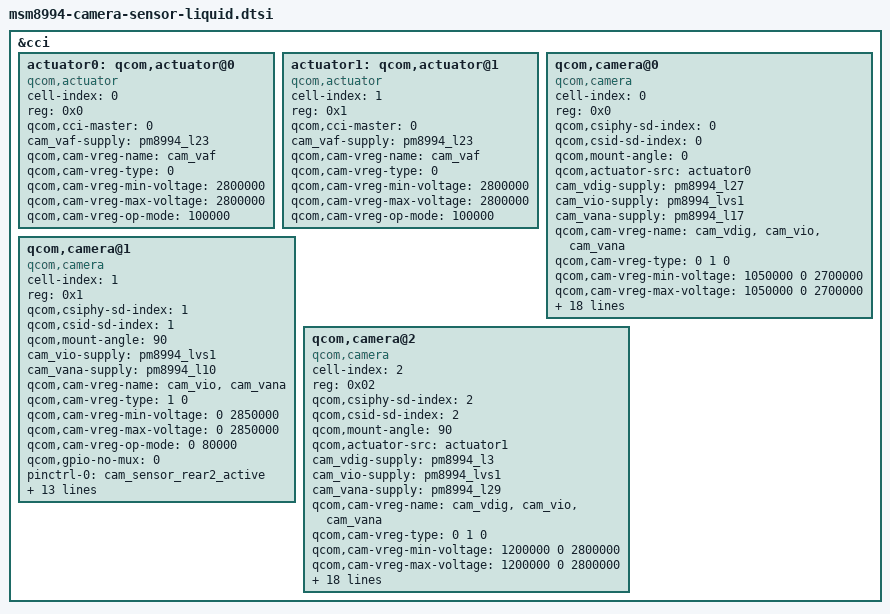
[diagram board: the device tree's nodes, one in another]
/*
 * Copyright (c) 2014, The Linux Foundation. All rights reserved.
 *
 * This program is free software; you can redistribute it and/or modify
 * it under the terms of the GNU General Public License version 2 and
 * only version 2 as published by the Free Software Foundation.
 *
 * This program is distributed in the hope that it will be useful,
 * but WITHOUT ANY WARRANTY; without even the implied warranty of
 * MERCHANTABILITY or FITNESS FOR A PARTICULAR PURPOSE.  See the
 * GNU General Public License for more details.
 */

&cci {
	actuator0: qcom,actuator@0 {
		cell-index = <0>;
		reg = <0x0>;
		compatible = "qcom,actuator";
		qcom,cci-master = <0>;
		cam_vaf-supply = <&pm8994_l23>;
		qcom,cam-vreg-name = "cam_vaf";
		qcom,cam-vreg-type = <0>;
		qcom,cam-vreg-min-voltage = <2800000>;
		qcom,cam-vreg-max-voltage = <2800000>;
		qcom,cam-vreg-op-mode = <100000>;
	};

	actuator1: qcom,actuator@1 {
		cell-index = <1>;
		reg = <0x1>;
		compatible = "qcom,actuator";
		qcom,cci-master = <0>;
		cam_vaf-supply = <&pm8994_l23>;
		qcom,cam-vreg-name = "cam_vaf";
		qcom,cam-vreg-type = <0>;
		qcom,cam-vreg-min-voltage = <2800000>;
		qcom,cam-vreg-max-voltage = <2800000>;
		qcom,cam-vreg-op-mode = <100000>;
	};

	qcom,camera@0 {
		cell-index = <0>;
		compatible = "qcom,camera";
		reg = <0x0>;
		qcom,csiphy-sd-index = <0>;
		qcom,csid-sd-index = <0>;
		qcom,mount-angle = <0>;
		qcom,actuator-src = <&actuator0>;
		cam_vdig-supply = <&pm8994_l27>;
		cam_vio-supply = <&pm8994_lvs1>;
		cam_vana-supply = <&pm8994_l17>;
		qcom,cam-vreg-name = "cam_vdig", "cam_vio", "cam_vana";
		qcom,cam-vreg-type = <0 1 0>;
		qcom,cam-vreg-min-voltage = <1050000 0 2700000>;
		qcom,cam-vreg-max-voltage = <1050000 0 2700000>;
		qcom,cam-vreg-op-mode = <105000 0 80000>;
		qcom,gpio-no-mux = <0>;
		pinctrl-names = "cam_default", "cam_suspend";
		pinctrl-0 = <&cam_sensor_mclk0_active &cam_sensor_rear_active>;
		pinctrl-1 = <&cam_sensor_mclk0_suspend &cam_sensor_rear_suspend>;
		gpios = <&msm_gpio 13 0>,
			<&msm_gpio 92 0>,
			<&msm_gpio 91 0>;
		qcom,gpio-reset = <1>;
		qcom,gpio-standby = <2>;
		qcom,gpio-req-tbl-num = <0 1 2>;
		qcom,gpio-req-tbl-flags = <1 0 0>;
		qcom,gpio-req-tbl-label = "CAMIF_MCLK0",
					  "CAM_RESET0",
					  "CAM_STANDBY0";
		qcom,sensor-position = <0>;
		qcom,sensor-mode = <0>;
		qcom,cci-master = <0>;
		status = "ok";
		clocks = <&clock_mmss clk_mclk0_clk_src>,
				<&clock_mmss clk_camss_mclk0_clk>;
		clock-names = "cam_src_clk", "cam_clk";
	};

	qcom,camera@1 {
		cell-index = <1>;
		compatible = "qcom,camera";
		reg = <0x1>;
		qcom,csiphy-sd-index = <1>;
		qcom,csid-sd-index = <1>;
		qcom,mount-angle = <90>;
		cam_vio-supply = <&pm8994_lvs1>;
		cam_vana-supply = <&pm8994_l10>;
		qcom,cam-vreg-name = "cam_vio", "cam_vana";
		qcom,cam-vreg-type = <1 0>;
		qcom,cam-vreg-min-voltage = <0 2850000>;
		qcom,cam-vreg-max-voltage = <0 2850000>;
		qcom,cam-vreg-op-mode = <0 80000>;
		qcom,gpio-no-mux = <0>;
		pinctrl-names = "cam_default", "cam_suspend";
		pinctrl-0 = <&cam_sensor_rear2_active>;
		pinctrl-1 = <&cam_sensor_rear2_suspend>;
		gpios = <&msm_gpio 14 0>,
			<&msm_gpio 94 0>;
		qcom,gpio-reset = <1>;
		qcom,gpio-standby = <2>;
		qcom,gpio-req-tbl-num = <0 1>;
		qcom,gpio-req-tbl-flags = <1 0>;
		qcom,gpio-req-tbl-label = "CAMIF_MCLK1",
					  "CAM_RESET1";
		qcom,sensor-position = <0>;
		qcom,sensor-mode = <0>;
		qcom,cci-master = <0>;
		status = "ok";
		clocks = <&clock_mmss clk_mclk1_clk_src>,
			<&clock_mmss clk_camss_mclk1_clk>;
		clock-names = "cam_src_clk", "cam_clk";
	};

	qcom,camera@2 {
		cell-index = <2>;
		compatible = "qcom,camera";
		reg = <0x02>;
		qcom,csiphy-sd-index = <2>;
		qcom,csid-sd-index = <2>;
		qcom,mount-angle = <90>;
		qcom,actuator-src = <&actuator1>;
		cam_vdig-supply = <&pm8994_l3>;
		cam_vio-supply = <&pm8994_lvs1>;
		cam_vana-supply = <&pm8994_l29>;
		qcom,cam-vreg-name = "cam_vdig", "cam_vio", "cam_vana";
		qcom,cam-vreg-type = <0 1 0>;
		qcom,cam-vreg-min-voltage = <1200000 0 2800000>;
		qcom,cam-vreg-max-voltage = <1200000 0 2800000>;
		qcom,cam-vreg-op-mode = <105000 0 80000>;
		qcom,gpio-no-mux = <0>;
		pinctrl-names = "cam_default", "cam_suspend";
		pinctrl-0 = <&cam_sensor_mclk2_active &cam_sensor_front_active>;
		pinctrl-1 = <&cam_sensor_mclk2_suspend &cam_sensor_front_suspend>;
		gpios = <&msm_gpio 15 0>,
			<&msm_gpio 104 0>,
			<&msm_gpio 105 0>;
		qcom,gpio-reset = <1>;
		qcom,gpio-standby = <2>;
		qcom,gpio-req-tbl-num = <0 1 2>;
		qcom,gpio-req-tbl-flags = <1 0 0>;
		qcom,gpio-req-tbl-label = "CAMIF_MCLK2",
					  "CAM_RESET2",
					  "CAM_STANDBY2";
		qcom,sensor-position = <1>;
		qcom,sensor-mode = <0>;
		qcom,cci-master = <0>;
		status = "ok";
		clocks = <&clock_mmss clk_mclk2_clk_src>,
			<&clock_mmss clk_camss_mclk2_clk>;
		clock-names = "cam_src_clk", "cam_clk";
	};
};
